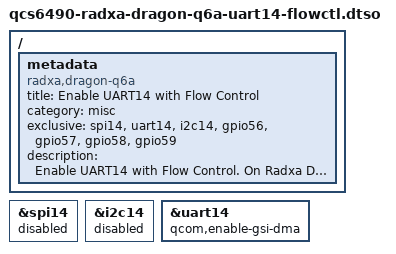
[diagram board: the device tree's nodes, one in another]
// SPDX-License-Identifier: BSD-3-Clause
/*
 * Copyright (c) 2026 Radxa Computer (Shenzhen) Co., Ltd.
 */

/dts-v1/;
/plugin/;

/ {
	metadata {
		title = "Enable UART14 with Flow Control";
		compatible = "radxa,dragon-q6a";
		category = "misc";
		exclusive = "spi14", "uart14", "i2c14", "gpio56", "gpio57", "gpio58", "gpio59";
		description = "Enable UART14 with Flow Control.
On Radxa Dragon Q6A, this is pin 22(rts), 33(cts), 37(tx), 36(rx).";
	};
};

&spi14 {
	status = "disabled";
};

&i2c14 {
	status = "disabled";
};

&uart14 {
	qcom,enable-gsi-dma;
	status = "okay";
};
